# M451_v1 register map
File version: 1.0
Registers are 32-bit, read-write, reset 0x0 unless marked. A register's access mark holds for its fields unless they carry their own. Offsets are from the block's base; [hi:lo] are bit positions; {n}, {i} and the like mark numbered series.

## PDMA — PDMA Register Map
Base 0x40008000; alternate view of DSCT_CTL
0x400 PDMA_CHCTL — PDMA Channel Control Register
  [11:0] CHENn — PDMA Channel Enable Bit. Set this bit to 1 to enable PDMAn operation. Channel cannot be active if it is not set as enabled. Note1: If software stops corresponding PDMA transfer by setting PDMA_STOP register, this bit will be cleared automatically after finishing current transfer. Note2: Software reset (writing 0xFFFF_FFFF to PDMA_STOP register) will also clear this bit. Note3: CHEN8~11 is M45xG/M45xE only.
    0=PDMA channel [n] Disabled; 1=PDMA channel [n] Enabled
0x404 PDMA_STOP wo — PDMA Transfer Stop Control Register
  [11:0] STOPn — PDMA Transfer Stop Control Register (Write Only). User can stop the PDMA transfer by STOPn bit field or by software reset (writing '0xFFFF_FFFF' to PDMA_STOP register). By bit field: By write 0xFFFF_FFFF to PDMA_STOP: Setting all PDMA_STOP bit to '1' will generate software reset to reset internal state machine (the DSCT will not be reset). When software reset, the operation will be stopped imminently that include the on-going transfer and the channel enable bit (PDMA_CHCTL [CHEN]) and request active flag will be cleared to '0'. Note1: User can read channel enable bit to know if the on-going transfer is finished. Note2: STOP8~11 is M45xG/M45xE only.
    0=No effect; 1=Stop PDMA transfer[n]. When software set PDMA_STOP bit, the operation will finish the on-going transfer channel and then clear the channel enable bit (PDMA_CHCTL [CHEN]) and request active flag
0x408 PDMA_SWREQ wo — PDMA Software Request Register
  [11:0] SWREQn — PDMA Software Request Register (Write Only). Set this bit to 1 to generate a software request to PDMA [n]. Note1: User can read PDMA_TRGSTS register to know which channel is on active. Active flag may be triggered by software request or peripheral request. Note2: If user does not enable corresponding PDMA channel, the software request will be ignored. Note3: SWREQ8~11 is M45xG/M45xE only.
    0=No effect; 1=Generate a software request
0x40C PDMA_TRGSTS ro — PDMA Channel Request Status Register
  [11:0] REQSTSn — PDMA Channel Request Status (Read Only). This flag indicates whether channel[n] have a request or not, no matter request from software or peripheral. When PDMA controller finishes channel transfer, this bit will be cleared automatically. Note1: If software stops corresponding PDMA transfer by setting PDMA_STOP register, this bit will be cleared automatically after finishing current transfer. Note2: Software reset (writing 0xFFFF_FFFF to PDMA_STOP register) will also clear this bit. Note3: REQSTS8~11 is M45xG/M45xE only.
    0=PDMA Channel n has no request; 1=PDMA Channel n has a request
0x410 PDMA_PRISET — PDMA Fixed Priority Setting Register
  [11:0] FPRISETn — PDMA Fixed Priority Setting Register. Set this bit to 1 to enable fixed priority level. Write Operation: Note1: This field only set to fixed priority, clear fixed priority use PDMA_PRICLR register. Note2: FPRISET8~11 is M45xG/M45xE only.
    0=No effect. Corresponding PDMA channel is round-robin priority; 1=Set PDMA channel [n] to fixed priority channel. Corresponding PDMA channel is fixed priority
0x414 PDMA_PRICLR wo — PDMA Fixed Priority Clear Register
  [11:0] FPRICLRn — PDMA Fixed Priority Clear Register (Write Only). Set this bit to 1 to clear fixed priority level. Note1: User can read PDMA_PRISET register to know the channel priority. Note2: FPRICLR8~11 is M45xG/M45xE only.
    0=No effect; 1=Clear PDMA channel [n] fixed priority setting
0x418 PDMA_INTEN — PDMA Interrupt Enable Register
  [11:0] INTENn — PDMA Interrupt Enable Register. This field is used for enabling PDMA channel[n] interrupt. Note: INTEN8~11 is M45xG/M45xE only.
    0=PDMA channel n interrupt Disabled; 1=PDMA channel n interrupt Enabled
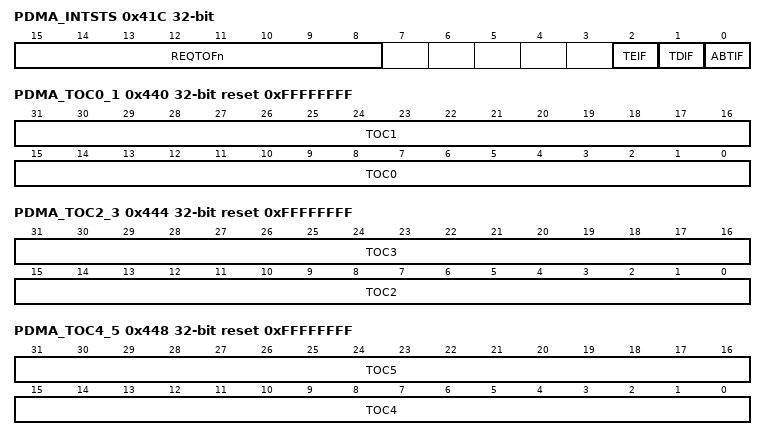
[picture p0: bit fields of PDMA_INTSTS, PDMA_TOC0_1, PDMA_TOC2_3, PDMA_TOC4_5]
0x41C PDMA_INTSTS — PDMA Interrupt Status Register
  [15:8] REQTOFn — Request Time-out Flag for Each Channel [N] (M45xD/M45xC Only). This flag indicates that PDMA controller has waited peripheral request for a period defined by PDMA_TOCn, user can write 1 to clear these bits.
    0=No request time-out; 1=Peripheral request time-out
  [2] TEIF ro — Table Empty Interrupt Flag (Read Only). This bit indicates that PDMA controller has finished each table transmission and the operation is Stop mode. User can read TEIF register to indicate which channel finished transfer.
    0=PDMA channel transfer is not finished; 1=PDMA channel transfer is finished and the operation is in idle state
  [1] TDIF ro — Transfer Done Interrupt Flag (Read Only). This bit indicates that PDMA controller has finished transmission; User can read PDMA_TDSTS register to indicate which channel finished transfer.
    0=Not finished yet; 1=PDMA channel has finished transmission
  [0] ABTIF — PDMA Read/Write Target Abort Interrupt Flag (Read-only). This bit indicates that PDMA has target abort error; Software can read PDMA_ABTSTS register to find which channel has target abort error.
    0=No AHB bus ERROR response received; 1=AHB bus ERROR response received
0x420 PDMA_ABTSTS — PDMA Channel Read/Write Target Abort Flag Register
  [11:0] ABTIFn — PDMA Read/Write Target Abort Interrupt Status Flag. This bit indicates which PDMA controller has target abort error; User can write 1 to clear these bits. Note: ABTIF8~11 is M45xG/M45xE only.
    0=No AHB bus ERROR response received when channel n transfer; 1=AHB bus ERROR response received when channel n transfer
0x424 PDMA_TDSTS — PDMA Channel Transfer Done Flag Register
  [11:0] TDIFn — Transfer Done Flag Register. This bit indicates whether PDMA controller channel transfer has been finished or not, user can write 1 to clear these bits. Note: TDIF8~11 is M45xG/M45xE only.
    0=PDMA channel transfer has not finished; 1=PDMA channel has finished transmission
0x428 PDMA_SCATSTS — PDMA Scatter-gather Table Empty Status Register
  [11:0] TEMPTYFn — Scatter-gather Table Empty Flag Register. This bit indicates which PDMA channel n Scatter Gather table is empty when SWREQn (PDMA_SWREQ[11:0]) set to high or channel has finished transmission and the operation mode is Stop mode. User can write 1 to clear these bits. Note: TEMPTYF8~11 is M45xG/M45xE only.
    0=PDMA channel scatter-gather table is not empty; 1=PDMA channel scatter-gather table is empty and PDMA SWREQ has be set
0x42C PDMA_TACTSTS ro — PDMA Transfer Active Flag Register
  [11:0] TXACTFn — Transfer on Active Flag Register (Read Only). This bit indicates which PDMA channel is in active. Note: TXACTF8~11 is M45xG/M45xE only.
    0=PDMA channel is not finished; 1=PDMA channel is active
0x434 PDMA_TOUTEN — PDMA Time-out Enable Register (M45xD/M45xC Only)
  [7:0] TOUTENn — PDMA Time-out Enable Bits
    0=PDMA Channel n time-out function Disable; 1=PDMA Channel n time-out function Enable
0x438 PDMA_TOUTIEN — PDMA Time-out Interrupt Enable Register (M45xD/M45xC Only)
  [7:0] TOUTIENn — PDMA Time-out Interrupt Enable Bits
    0=PDMA Channel n time-out interrupt Disable; 1=PDMA Channel n time-out interrupt Enable
0x43C PDMA_SCATBA reset 0x20000000 — PDMA Scatter-gather Descriptor Table Base Address Register
  [31:16] SCATBA — PDMA Scatter-gather Descriptor Table Address Register. In Scatter-Gather mode, this is the base address for calculating the next link - list address. The next link address equation is. Note: Only useful in Scatter-Gather mode.
0x440 PDMA_TOC0_1 reset 0xFFFFFFFF — PDMA Time-out Counter Ch1 and Ch0 Register (M45xD/M45xC Only)
  [31:16] TOC1 — Time-out Counter for Channel 1. This controls the period of time-out function for channel 1. The calculation unit is based on 10 kHz clock.
  [15:0] TOC0 — Time-out Counter for Channel 0. This controls the period of time-out function for channel 0. The calculation unit is based on 10 kHz clock.
0x444 PDMA_TOC2_3 reset 0xFFFFFFFF — PDMA Time-out Counter Ch3 and Ch2 Register (M45xD/M45xC Only)
  [31:16] TOC3 — Time-out Period Counter for Channel 3. This controls the period of time-out function for channel 3. The calculation unit is based on 10 kHz clock.
  [15:0] TOC2 — Time-out Period Counter for Channel 2. This controls the period of time-out function for channel 2. The calculation unit is based on 10 kHz clock.
0x448 PDMA_TOC4_5 reset 0xFFFFFFFF — PDMA Time-out Counter Ch5 and Ch4 Register (M45xD/M45xC Only)
  [31:16] TOC5 — Time-out Period Counter for Channel 5. This controls the period of time-out function for channel 5. The calculation unit is based on 10 kHz clock.
  [15:0] TOC4 — Time-out Period Counter for Channel 4. This controls the period of time-out function for channel 4. The calculation unit is based on 10 kHz clock.
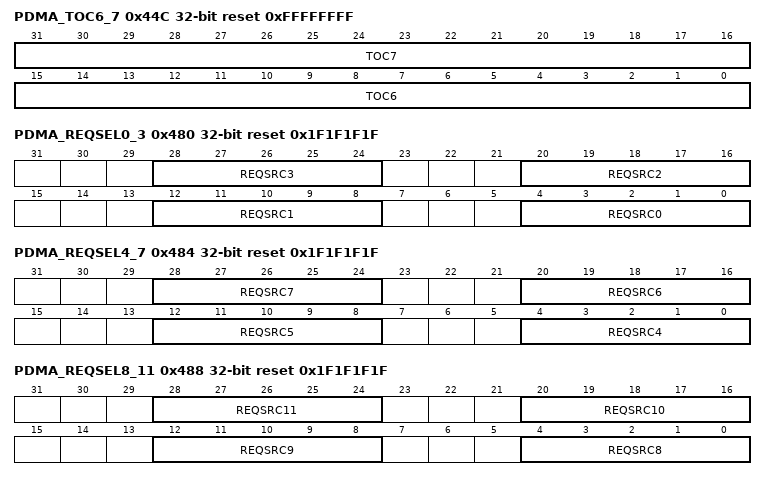
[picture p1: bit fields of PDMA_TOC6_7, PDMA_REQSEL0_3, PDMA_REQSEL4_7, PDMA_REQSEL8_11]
0x44C PDMA_TOC6_7 reset 0xFFFFFFFF — PDMA Time-out Counter Ch7 and Ch6 Register (M45xD/M45xC Only)
  [31:16] TOC7 — Time-out Period Counter for Channel 7. This controls the period of time-out function for channel 7. The calculation unit is based on 10 kHz clock.
  [15:0] TOC6 — Time-out Period Counter for Channel 6. This controls the period of time-out function for channel 6. The calculation unit is based on 10 kHz clock.
0x480 PDMA_REQSEL0_3 reset 0x1F1F1F1F — PDMA Request Source Select Register 0
  [28:24] REQSRC3 — Channel 3 Request Source Selection. This filed defines which peripheral is connected to PDMA channel 3. User can configure the peripheral setting by REQSRC3. Note: The channel configuration is the same as REQSRC0 field. Please refer to the explanation of REQSRC0.
  [20:16] REQSRC2 — Channel 2 Request Source Selection. This filed defines which peripheral is connected to PDMA channel 2. User can configure the peripheral setting by REQSRC2. Note: The channel configuration is the same as REQSRC0 field. Please refer to the explanation of REQSRC0.
  [12:8] REQSRC1 — Channel 1 Request Source Selection. This filed defines which peripheral is connected to PDMA channel 1. User can configure the peripheral setting by REQSRC1. Note: The channel configuration is the same as REQSRC0 field. Please refer to the explanation of REQSRC0.
  [4:0] REQSRC0 — Channel 0 Request Source Selection. This filed defines which peripheral is connected to PDMA channel 0. User can configure the peripheral by setting REQSRC0. Note 1: A peripheral can't assign to two channels at the same time. Note 2: This field is useless when transfer between memory and memory.
    1=Channel connects to SPI0_TX; 2=Channel connects to SPI1_TX; 3=Channel connects to SPI2_TX; {v}=Channel connects to UART{v-4}_TX (v=4..7); 8=Channel connects to DAC_TX; 9=Channel connects to ADC_RX; 11=Channel connects to PWM0_P1_RX; 12=Channel connects to PWM0_P2_RX; 13=Channel connects to PWM0_P3_RX; 14=Channel connects to PWM1_P1_RX; 15=Channel connects to PWM1_P2_RX; 16=Channel connects to PWM1_P3_RX; 17=Channel connects to SPI0_RX; 18=Channel connects to SPI1_RX; 19=Channel connects to SPI2_RX; {v}=Channel connects to UART{v-20}_RX (v=20..23); 31=Disable PDMA
0x484 PDMA_REQSEL4_7 reset 0x1F1F1F1F — PDMA Request Source Select Register 1
  [8n-28:8n-32] REQSRC{n} (n=4..7) — Channel {n} Request Source Selection. This filed defines which peripheral is connected to PDMA channel {n}. User can configure the peripheral setting by REQSRC{n}. Note: The channel configuration is the same as REQSRC0 field. Please refer to the explanation of REQSRC0.
0x488 PDMA_REQSEL8_11 reset 0x1F1F1F1F — PDMA Request Source Select Register 2
  [8n-60:8n-64] REQSRC{n} (n=8..11) — Channel {n} Request Source Selection. This filed defines which peripheral is connected to PDMA channel {n}. User can configure the peripheral setting by REQSRC{n}. Note: The channel configuration is the same as REQSRC0 field. Please refer to the explanation of REQSRC0.
